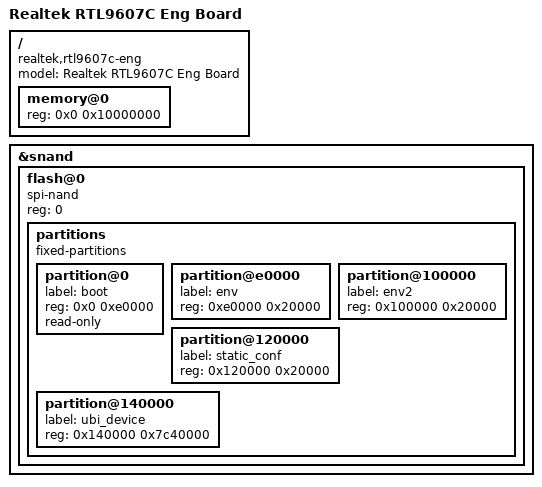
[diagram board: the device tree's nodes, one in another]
// SPDX-License-Identifier: GPL-2.0-or-later OR MIT

/dts-v1/;

#include "rtl9607c.dtsi"
#include <dt-bindings/gpio/gpio.h>
#include <dt-bindings/input/input.h>

/ {
	compatible = "realtek,rtl9607c-eng", "realtek,rtl9607c-soc";

	model = "Realtek RTL9607C Eng Board";

	memory@0 {
		device_type = "memory";
		reg = <0x0 0x10000000>;
		};
};

&snand {
	status= "okay";

	flash@0 {
		compatible = "spi-nand";
		reg = <0>;

		partitions {
			compatible = "fixed-partitions";
			#address-cells = <1>;
			#size-cells = <1>;

			partition@0 {
				label = "boot";
				reg = <0x0 0xe0000>;
				read-only;
			};

			partition@e0000 {
				label = "env";
				reg = <0xe0000 0x20000>;
			};

			partition@100000 {
				label = "env2";
				reg = <0x100000 0x20000>;
			};

			partition@120000 {
				label = "static_conf";
				reg = <0x120000 0x20000>;
			};

			partition@140000 {
				label = "ubi_device";
				reg = <0x140000 0x7c40000>;
			};
		};
	};
};
